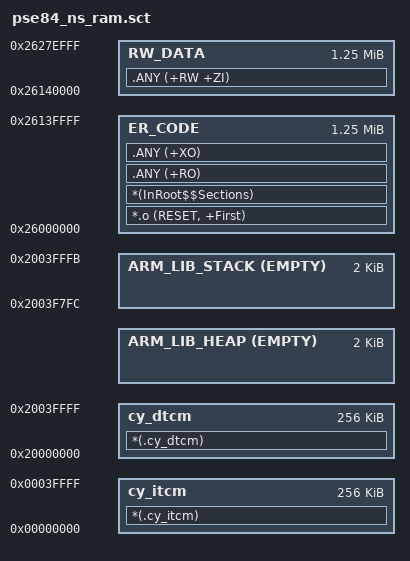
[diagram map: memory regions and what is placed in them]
#! armclang -E --target=arm-arm-none-eabi -mcpu=cortex-m55 -xc
; command above MUST be in first line (no comment above!)


/*----------------------------------------------------------------------------*/
#define __ITCM_BASE      0x00000000
#define __ITCM_SIZE      0x00040000

/*--------------------- Embedded DTCM Configuration ---------------------------
; <h> DTCM Configuration
;   <o0> DTCM Base Address    <0x0-0xFFFFFFFF:8>
;   <o1> DTCM Size (in Bytes) <0x0-0xFFFFFFFF:8>
; </h>
 *----------------------------------------------------------------------------*/
#define __DTCM_BASE      0x20000000
#define __DTCM_SIZE      0x00040000

/*--------------------- Stack / Heap Configuration ---------------------------
; <h> Stack / Heap Configuration
;   <o0> Stack Size (in Bytes) <0x0-0xFFFFFFFF:8>
;   <o1> Heap Size (in Bytes) <0x0-0xFFFFFFFF:8>
; </h>
 *----------------------------------------------------------------------------*/
#define __STACK_SIZE    0x00000800
#define __HEAP_SIZE     0x00000800

/*------------------------SOCMEM------------------------------------------------*/
#define SOCMEM_NS_SAHB_START 0x26000000
#define SOCMEM_NS_SAHB_SIZE 0x00500000

#define SOCMEM_START               SOCMEM_NS_SAHB_START
#define SOCMEM_SIZE                SOCMEM_NS_SAHB_SIZE
/*
;------------- <<< end of configuration section >>> ---------------------------
*/


/*----------------------------------------------------------------------------
  User Stack & Heap boundary definition
 *----------------------------------------------------------------------------*/
#define __STACK_TOP    (__DTCM_BASE + __DTCM_SIZE - 4)    /* starts at end of DTCM */
#define __HEAP_BASE    (AlignExpr(+0, 8))           /* starts after RW_DTCM section, 8 byte aligned */


/*----------------------------------------------------------------------------
  Scatter File Definitions definition
 *----------------------------------------------------------------------------*/
#define __RO_BASE       SOCMEM_START
#define __RO_SIZE       (SOCMEM_SIZE / 4)

#define __RW_BASE       __RO_BASE + __RO_SIZE
#define __RW_SIZE      ((SOCMEM_SIZE / 4) - __STACK_SIZE - __HEAP_SIZE)


LR_CODE __RO_BASE __RO_SIZE  {                       ; load region size_region
  ER_CODE __RO_BASE __RO_SIZE  {                     ; load address = execution address
   *.o (RESET, +First)
   *(InRoot$$Sections)
;   *(Veneer$$CMSE)                                  ; uncomment for secure applications
   .ANY (+RO)
   .ANY (+XO)
  }

  RW_DATA __RW_BASE __RW_SIZE  {                     ; RW data
   .ANY (+RW +ZI)
  }

  cy_itcm __ITCM_BASE __ITCM_SIZE  {
    *(.cy_itcm)
  }

  cy_dtcm __DTCM_BASE __DTCM_SIZE  {
    *(.cy_dtcm)
  }

  #if __HEAP_SIZE > 0
  ARM_LIB_HEAP  __HEAP_BASE EMPTY  __HEAP_SIZE  {   ; Reserve empty region for heap
  }
#endif

  ARM_LIB_STACK __STACK_TOP EMPTY -__STACK_SIZE {   ; Reserve empty region for stack
  }


}
